AUTOSAR XML (schema 00052)
package /apd/AdaptiveApplicationSwComponentTypes
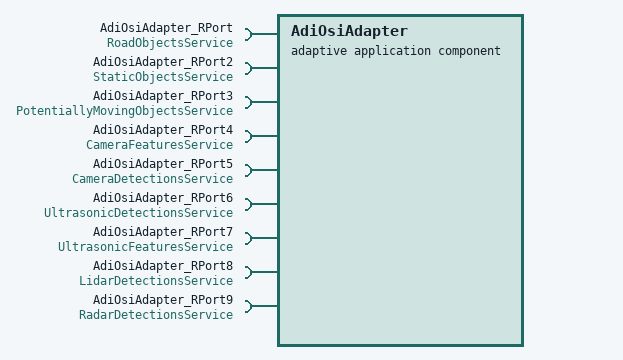
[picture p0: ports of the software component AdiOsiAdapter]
  adaptive application sw component type AdiOsiAdapter
    9 x require port:
      AdiOsiAdapter_RPort: required-interface=RoadObjectsService
      AdiOsiAdapter_RPort2: required-interface=StaticObjectsService
      AdiOsiAdapter_RPort3: required-interface=PotentiallyMovingObjectsService
      AdiOsiAdapter_RPort4: required-interface=CameraFeaturesService
      AdiOsiAdapter_RPort5: required-interface=CameraDetectionsService
      AdiOsiAdapter_RPort6: required-interface=UltrasonicDetectionsService
      AdiOsiAdapter_RPort7: required-interface=UltrasonicFeaturesService
      AdiOsiAdapter_RPort8: required-interface=LidarDetectionsService
      AdiOsiAdapter_RPort9: required-interface=RadarDetectionsService
package /apd/Executables
  executable AdiOsiAdapter: category=APPLICATION_LEVEL, minimum-timer-granularity=1000.0
    root sw component prototype AdiOsiAdapter: application-type=AdiOsiAdapter
